# AT91SAM9G20 register map
Vendor: Atmel; File version: 20130207
CPU: 
Registers are 32-bit, read-write, reset 0x0 unless marked. A register's access mark holds for its fields unless they carry their own. Offsets are from the block's base; [hi:lo] are bit positions; {n}, {i} and the like mark numbered series.

## ISI — Image Sensor Interface
Base 0xFFFC0000; register names take the prefix ISI_
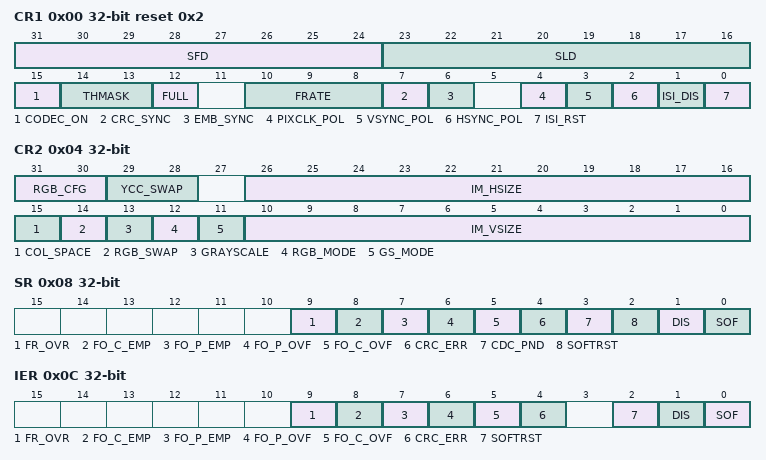
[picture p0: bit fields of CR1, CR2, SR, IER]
0x00 CR1 reset 0x2 — ISI Control 1 Register
  [31:24] SFD — Start of Frame Delay
  [23:16] SLD — Start of Line Delay
  [15] CODEC_ON — Enable the codec path enable bit
  [14:13] THMASK — Threshold mask
  [12] FULL — Full mode is allowed
  [10:8] FRATE — Frame rate [0..7]
  [7] CRC_SYNC — Embedded synchronization
  [6] EMB_SYNC — Embedded synchronization
  [4] PIXCLK_POL — Pixel clock polarity
  [3] VSYNC_POL — Vertical synchronization polarity
  [2] HSYNC_POL — Horizontal synchronization polarity
  [1] ISI_DIS — Image sensor disable:
  [0] ISI_RST — Image sensor interface reset
0x04 CR2 — ISI Control 2 Register
  [31:30] RGB_CFG — Defines RGB pattern when RGB_MODE is set to 1
  [29:28] YCC_SWAP — Defines the YCC image data
  [26:16] IM_HSIZE — Horizontal size of the Image sensor [0..2047]
  [15] COL_SPACE — Color space for the image data
  [14] RGB_SWAP
  [13] GRAYSCALE
  [12] RGB_MODE — RGB input mode
  [11] GS_MODE
  [10:0] IM_VSIZE — Vertical size of the Image sensor [0..2047]
0x08 SR ro — ISI Status Register
  [9] FR_OVR — Frame rate overrun
  [8] FO_C_EMP
  [7] FO_P_EMP
  [6] FO_P_OVF — FIFO preview overflow
  [5] FO_C_OVF — FIFO codec overflow
  [4] CRC_ERR — CRC synchronization error
  [3] CDC_PND — Codec request pending
  [2] SOFTRST — Software reset
  [1] DIS — Image Sensor Interface disable
  [0] SOF — Start of frame
0x0C IER — ISI Interrupt Enable Register
  [9] FR_OVR — Frame overrun
  [8] FO_C_EMP
  [7] FO_P_EMP
  [6] FO_P_OVF — FIFO preview Overflow
  [5] FO_C_OVF — FIFO codec Overflow
  [4] CRC_ERR — CRC synchronization error
  [2] SOFTRST — Soft Reset
  [1] DIS — Image Sensor Interface disable
  [0] SOF — Start of Frame
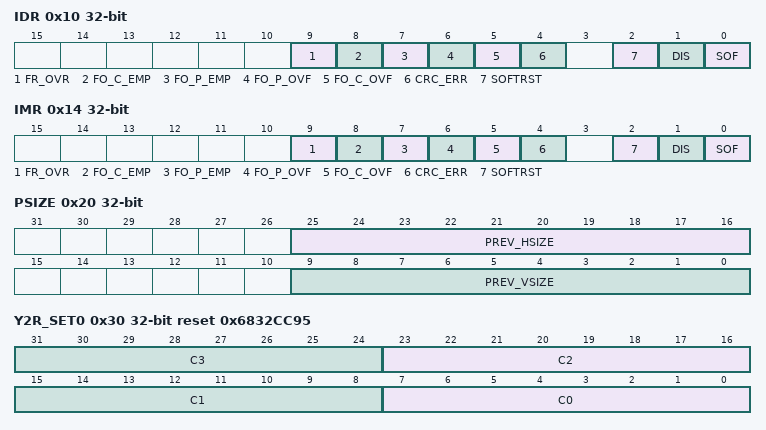
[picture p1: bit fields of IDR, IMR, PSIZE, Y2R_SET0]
0x10 IDR — ISI Interrupt Disable Register
  [9] FR_OVR
  [8] FO_C_EMP
  [7] FO_P_EMP
  [6] FO_P_OVF — FIFO preview overflow
  [5] FO_C_OVF — FIFO codec overflow
  [4] CRC_ERR — CRC synchronization error
  [2] SOFTRST
  [1] DIS — Image Sensor Interface disable
  [0] SOF — Start of Frame
0x14 IMR — ISI Interrupt Mask Register
  [9] FR_OVR — Frame Rate Overrun
  [8] FO_C_EMP
  [7] FO_P_EMP
  [6] FO_P_OVF — FIFO preview overflow
  [5] FO_C_OVF — FIFO codec overflow
  [4] CRC_ERR — CRC synchronization error
  [2] SOFTRST
  [1] DIS — Image sensor interface disable
  [0] SOF — Start of Frame
0x20 PSIZE — ISI Preview Size Register
  [25:16] PREV_HSIZE — Horizontal size for the preview path
  [9:0] PREV_VSIZE — Vertical size for the preview path
0x24 PDECF reset 0x10 — ISI Preview Decimation Factor Register
  [7:0] DEC_FACTOR — Decimation factor
0x28 PPFBD — ISI Preview Primary FBD Register
  [31:0] PREV_FBD_ADDR — Base address for preview frame buffer descriptor
0x2C CDBA — ISI Codec DMA Base Address Register
  [31:0] CODEC_DMA_ADDR — Base address for codec DMA
0x30 Y2R_SET0 reset 0x6832CC95 — ISI CSC YCrCb To RGB Set 0 Register
  [8n+7:8n] C{n} (n=0..3) — Color Space Conversion Matrix Coefficient C{n}
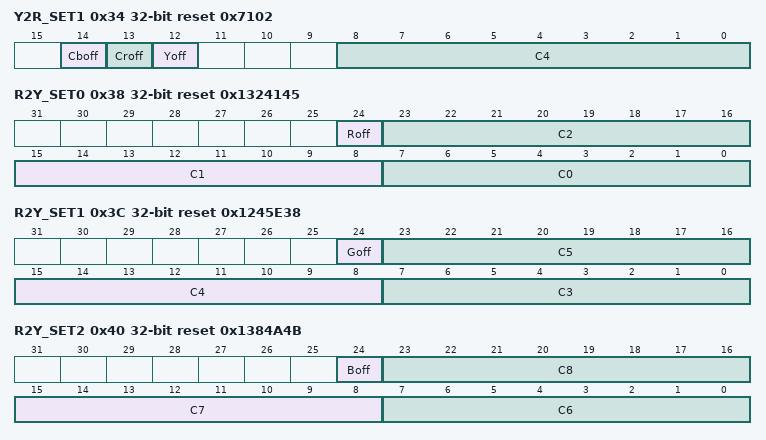
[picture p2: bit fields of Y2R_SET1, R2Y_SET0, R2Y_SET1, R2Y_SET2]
0x34 Y2R_SET1 reset 0x7102 — ISI CSC YCrCb To RGB Set 1 Register
  [14] Cboff — Color Space Conversion Blue Chrominance default offset
  [13] Croff — Color Space Conversion Red Chrominance default offset
  [12] Yoff — Color Space Conversion Luminance default offset
  [8:0] C4 — Color Space Conversion Matrix coefficient C4
0x38 R2Y_SET0 reset 0x1324145 — ISI CSC RGB To YCrCb Set 0 Register
  [24] Roff — Color Space Conversion Red component offset
  [23:16] C2 — Color Space Conversion Matrix coefficient C2
  [15:8] C1 — Color Space Conversion Matrix coefficient C1
  [7:0] C0 — Color Space Conversion Matrix coefficient C0
0x3C R2Y_SET1 reset 0x1245E38 — ISI CSC RGB To YCrCb Set 1 Register
  [24] Goff — Color Space Conversion Green component offset
  [23:16] C5 — Color Space Conversion Matrix coefficient C5
  [15:8] C4 — Color Space Conversion Matrix coefficient C4
  [7:0] C3 — Color Space Conversion Matrix coefficient C3
0x40 R2Y_SET2 reset 0x1384A4B — ISI CSC RGB To YCrCb Set 2 Register
  [24] Boff — Color Space Conversion Blue component offset
  [23:16] C8 — Color Space Conversion Matrix coefficient C8
  [15:8] C7 — Color Space Conversion Matrix coefficient C7
  [7:0] C6 — Color Space Conversion Matrix coefficient C6
